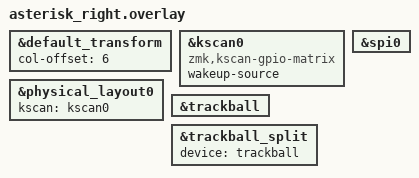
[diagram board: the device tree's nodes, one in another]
#include "asterisk.dtsi"
#include "asterisk_3610.dtsi"

&default_transform {
	col-offset = <6>;
};

&kscan0 {
    compatible = "zmk,kscan-gpio-matrix";
    wakeup-source;
};

&physical_layout0 {
        kscan = <&kscan0>;
};

&spi0 {
    status = "okay";
};

&trackball {
    status = "okay";
};

&trackball {
  status = "okay";
};

/* Enable the trackball listener on the peripheral with the sensor */
&trackball_split {
  device = <&trackball>;
  status = "okay";
};
 


